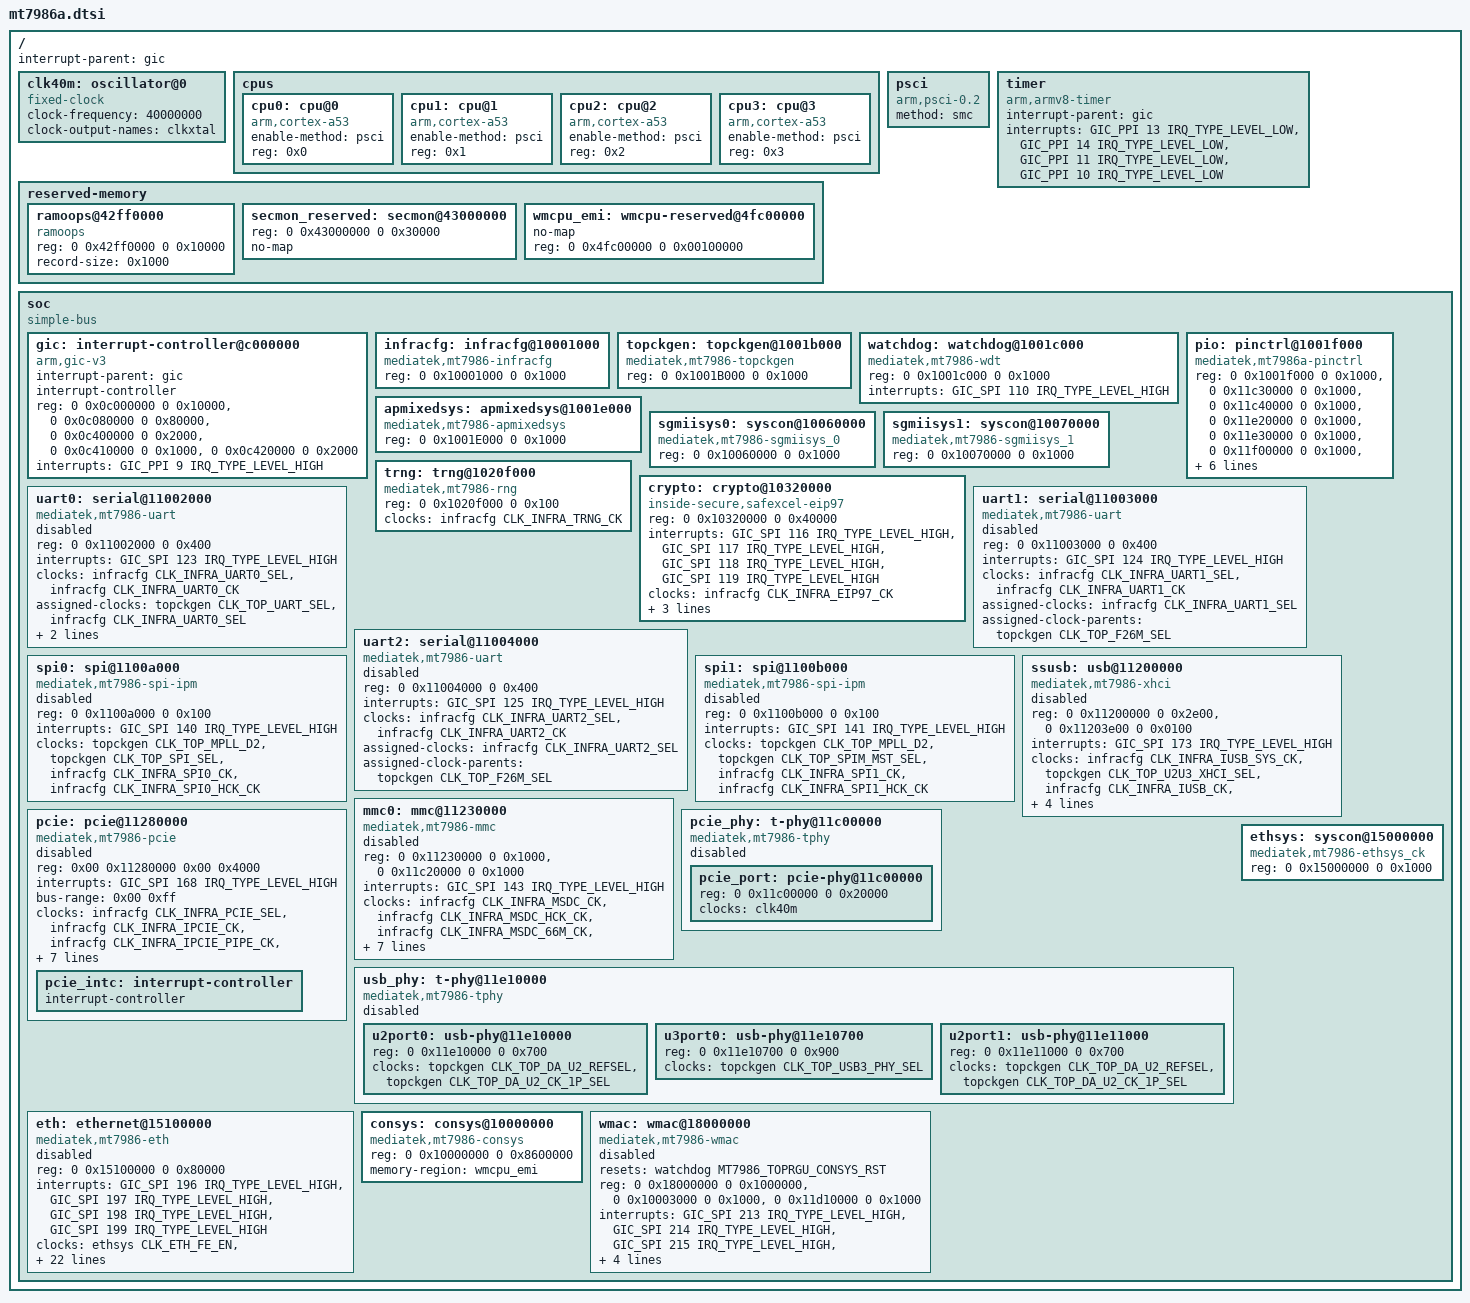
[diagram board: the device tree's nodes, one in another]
// SPDX-License-Identifier: (GPL-2.0 OR MIT)
/*
 * Copyright (C) 2021 MediaTek Inc.
 * Author: Sam.Shih <sam.shih@mediatek.com>
 */

#include <dt-bindings/clock/mt7986-clk.h>
#include <dt-bindings/interrupt-controller/irq.h>
#include <dt-bindings/interrupt-controller/arm-gic.h>
#include <dt-bindings/phy/phy.h>
#include <dt-bindings/reset/mt7986-resets.h>

/ {
	interrupt-parent = <&gic>;
	#address-cells = <2>;
	#size-cells = <2>;

	clk40m: oscillator@0 {
		compatible = "fixed-clock";
		clock-frequency = <40000000>;
		#clock-cells = <0>;
		clock-output-names = "clkxtal";
	};

	cpus {
		#address-cells = <1>;
		#size-cells = <0>;
		cpu0: cpu@0 {
			device_type = "cpu";
			compatible = "arm,cortex-a53";
			enable-method = "psci";
			reg = <0x0>;
			#cooling-cells = <2>;
		};

		cpu1: cpu@1 {
			device_type = "cpu";
			compatible = "arm,cortex-a53";
			enable-method = "psci";
			reg = <0x1>;
			#cooling-cells = <2>;
		};

		cpu2: cpu@2 {
			device_type = "cpu";
			compatible = "arm,cortex-a53";
			enable-method = "psci";
			reg = <0x2>;
			#cooling-cells = <2>;
		};

		cpu3: cpu@3 {
			device_type = "cpu";
			enable-method = "psci";
			compatible = "arm,cortex-a53";
			reg = <0x3>;
			#cooling-cells = <2>;
		};
	};

	psci {
		compatible  = "arm,psci-0.2";
		method      = "smc";
	};

	reserved-memory {
		#address-cells = <2>;
		#size-cells = <2>;
		ranges;

		/* 64 KiB reserved for ramoops/pstore */
		ramoops@42ff0000 {
			compatible = "ramoops";
			reg = <0 0x42ff0000 0 0x10000>;
			record-size = <0x1000>;
		};

		/* 192 KiB reserved for ARM Trusted Firmware (BL31) */
		secmon_reserved: secmon@43000000 {
			reg = <0 0x43000000 0 0x30000>;
			no-map;
		};

		wmcpu_emi: wmcpu-reserved@4fc00000 {
			no-map;
			reg = <0 0x4fc00000 0 0x00100000>;
		};
	};

	timer {
		compatible = "arm,armv8-timer";
		interrupt-parent = <&gic>;
		interrupts = <GIC_PPI 13 IRQ_TYPE_LEVEL_LOW>,
			     <GIC_PPI 14 IRQ_TYPE_LEVEL_LOW>,
			     <GIC_PPI 11 IRQ_TYPE_LEVEL_LOW>,
			     <GIC_PPI 10 IRQ_TYPE_LEVEL_LOW>;
	};

	soc {
		#address-cells = <2>;
		#size-cells = <2>;
		compatible = "simple-bus";
		ranges;

		gic: interrupt-controller@c000000 {
			compatible = "arm,gic-v3";
			#interrupt-cells = <3>;
			interrupt-parent = <&gic>;
			interrupt-controller;
			reg = <0 0x0c000000 0 0x10000>,  /* GICD */
			      <0 0x0c080000 0 0x80000>,  /* GICR */
			      <0 0x0c400000 0 0x2000>,   /* GICC */
			      <0 0x0c410000 0 0x1000>,   /* GICH */
			      <0 0x0c420000 0 0x2000>;   /* GICV */
			interrupts = <GIC_PPI 9 IRQ_TYPE_LEVEL_HIGH>;
		};

		infracfg: infracfg@10001000 {
			compatible = "mediatek,mt7986-infracfg", "syscon";
			reg = <0 0x10001000 0 0x1000>;
			#clock-cells = <1>;
		};

		topckgen: topckgen@1001b000 {
			compatible = "mediatek,mt7986-topckgen", "syscon";
			reg = <0 0x1001B000 0 0x1000>;
			#clock-cells = <1>;
		};

		watchdog: watchdog@1001c000 {
			compatible = "mediatek,mt7986-wdt",
				     "mediatek,mt6589-wdt";
			reg = <0 0x1001c000 0 0x1000>;
			interrupts = <GIC_SPI 110 IRQ_TYPE_LEVEL_HIGH>;
			#reset-cells = <1>;
		};

		pio: pinctrl@1001f000 {
			compatible = "mediatek,mt7986a-pinctrl";
			reg = <0 0x1001f000 0 0x1000>,
			      <0 0x11c30000 0 0x1000>,
			      <0 0x11c40000 0 0x1000>,
			      <0 0x11e20000 0 0x1000>,
			      <0 0x11e30000 0 0x1000>,
			      <0 0x11f00000 0 0x1000>,
			      <0 0x11f10000 0 0x1000>,
			      <0 0x1000b000 0 0x1000>;
			reg-names = "gpio", "iocfg_rt", "iocfg_rb", "iocfg_lt",
				    "iocfg_lb", "iocfg_tr", "iocfg_tl", "eint";
			gpio-controller;
			#gpio-cells = <2>;
			gpio-ranges = <&pio 0 0 100>;
			interrupt-controller;
			interrupts = <GIC_SPI 225 IRQ_TYPE_LEVEL_HIGH>;
			interrupt-parent = <&gic>;
			#interrupt-cells = <2>;
		};

		apmixedsys: apmixedsys@1001e000 {
			compatible = "mediatek,mt7986-apmixedsys";
			reg = <0 0x1001E000 0 0x1000>;
			#clock-cells = <1>;
		};

		sgmiisys0: syscon@10060000 {
			compatible = "mediatek,mt7986-sgmiisys_0",
				     "syscon";
			reg = <0 0x10060000 0 0x1000>;
			#clock-cells = <1>;
		};

		sgmiisys1: syscon@10070000 {
			compatible = "mediatek,mt7986-sgmiisys_1",
				     "syscon";
			reg = <0 0x10070000 0 0x1000>;
			#clock-cells = <1>;
		};

		trng: trng@1020f000 {
			compatible = "mediatek,mt7986-rng";
			reg = <0 0x1020f000 0 0x100>;
			clocks = <&infracfg CLK_INFRA_TRNG_CK>;
			clock-names = "rng";
			status = "okay";
		};

		crypto: crypto@10320000 {
			compatible = "inside-secure,safexcel-eip97";
			reg = <0 0x10320000 0 0x40000>;
			interrupts = <GIC_SPI 116 IRQ_TYPE_LEVEL_HIGH>,
				     <GIC_SPI 117 IRQ_TYPE_LEVEL_HIGH>,
				     <GIC_SPI 118 IRQ_TYPE_LEVEL_HIGH>,
				     <GIC_SPI 119 IRQ_TYPE_LEVEL_HIGH>;
			interrupt-names = "ring0", "ring1", "ring2", "ring3";
			clocks = <&infracfg CLK_INFRA_EIP97_CK>;
			clock-names = "infra_eip97_ck";
			assigned-clocks = <&topckgen CLK_TOP_EIP_B_SEL>;
			assigned-clock-parents = <&apmixedsys CLK_APMIXED_NET2PLL>;
			status = "okay";
		};

		uart0: serial@11002000 {
			compatible = "mediatek,mt7986-uart",
				     "mediatek,mt6577-uart";
			reg = <0 0x11002000 0 0x400>;
			interrupts = <GIC_SPI 123 IRQ_TYPE_LEVEL_HIGH>;
			clocks = <&infracfg CLK_INFRA_UART0_SEL>,
				 <&infracfg CLK_INFRA_UART0_CK>;
			clock-names = "baud", "bus";
			assigned-clocks = <&topckgen CLK_TOP_UART_SEL>,
					  <&infracfg CLK_INFRA_UART0_SEL>;
			assigned-clock-parents = <&topckgen CLK_TOP_XTAL>,
						 <&topckgen CLK_TOP_UART_SEL>;
			status = "disabled";
		};

		uart1: serial@11003000 {
			compatible = "mediatek,mt7986-uart",
				     "mediatek,mt6577-uart";
			reg = <0 0x11003000 0 0x400>;
			interrupts = <GIC_SPI 124 IRQ_TYPE_LEVEL_HIGH>;
			clocks = <&infracfg CLK_INFRA_UART1_SEL>,
				 <&infracfg CLK_INFRA_UART1_CK>;
			clock-names = "baud", "bus";
			assigned-clocks = <&infracfg CLK_INFRA_UART1_SEL>;
			assigned-clock-parents = <&topckgen CLK_TOP_F26M_SEL>;
			status = "disabled";
		};

		uart2: serial@11004000 {
			compatible = "mediatek,mt7986-uart",
				     "mediatek,mt6577-uart";
			reg = <0 0x11004000 0 0x400>;
			interrupts = <GIC_SPI 125 IRQ_TYPE_LEVEL_HIGH>;
			clocks = <&infracfg CLK_INFRA_UART2_SEL>,
				 <&infracfg CLK_INFRA_UART2_CK>;
			clock-names = "baud", "bus";
			assigned-clocks = <&infracfg CLK_INFRA_UART2_SEL>;
			assigned-clock-parents = <&topckgen CLK_TOP_F26M_SEL>;
			status = "disabled";
		};

		spi0: spi@1100a000 {
			compatible = "mediatek,mt7986-spi-ipm", "mediatek,spi-ipm";
			reg = <0 0x1100a000 0 0x100>;
			interrupts = <GIC_SPI 140 IRQ_TYPE_LEVEL_HIGH>;
			clocks = <&topckgen CLK_TOP_MPLL_D2>,
				 <&topckgen CLK_TOP_SPI_SEL>,
				 <&infracfg CLK_INFRA_SPI0_CK>,
				 <&infracfg CLK_INFRA_SPI0_HCK_CK>;
			clock-names = "parent-clk", "sel-clk", "spi-clk", "hclk";
			status = "disabled";
		};

		spi1: spi@1100b000 {
			compatible = "mediatek,mt7986-spi-ipm", "mediatek,spi-ipm";
			reg = <0 0x1100b000 0 0x100>;
			interrupts = <GIC_SPI 141 IRQ_TYPE_LEVEL_HIGH>;
			clocks = <&topckgen CLK_TOP_MPLL_D2>,
				 <&topckgen CLK_TOP_SPIM_MST_SEL>,
				 <&infracfg CLK_INFRA_SPI1_CK>,
				 <&infracfg CLK_INFRA_SPI1_HCK_CK>;
			clock-names = "parent-clk", "sel-clk", "spi-clk", "hclk";
			status = "disabled";
		};

		ssusb: usb@11200000 {
			compatible = "mediatek,mt7986-xhci",
				     "mediatek,mtk-xhci";
			reg = <0 0x11200000 0 0x2e00>,
			      <0 0x11203e00 0 0x0100>;
			reg-names = "mac", "ippc";
			interrupts = <GIC_SPI 173 IRQ_TYPE_LEVEL_HIGH>;
			clocks = <&infracfg CLK_INFRA_IUSB_SYS_CK>,
				 <&topckgen CLK_TOP_U2U3_XHCI_SEL>,
				 <&infracfg CLK_INFRA_IUSB_CK>,
				 <&infracfg CLK_INFRA_IUSB_133_CK>,
				 <&infracfg CLK_INFRA_IUSB_66M_CK>;
			clock-names = "sys_ck",
				      "xhci_ck",
				      "ref_ck",
				      "mcu_ck",
				      "dma_ck";
			phys = <&u2port0 PHY_TYPE_USB2>,
			       <&u3port0 PHY_TYPE_USB3>,
			       <&u2port1 PHY_TYPE_USB2>;
			status = "disabled";
		};

		mmc0: mmc@11230000 {
			compatible = "mediatek,mt7986-mmc";
			reg = <0 0x11230000 0 0x1000>,
			      <0 0x11c20000 0 0x1000>;
			interrupts = <GIC_SPI 143 IRQ_TYPE_LEVEL_HIGH>;
			clocks = <&infracfg CLK_INFRA_MSDC_CK>,
				 <&infracfg CLK_INFRA_MSDC_HCK_CK>,
				 <&infracfg CLK_INFRA_MSDC_66M_CK>,
				 <&infracfg CLK_INFRA_MSDC_133M_CK>;
			clock-names = "source", "hclk", "axi_cg", "ahb_cg";
			assigned-clocks = <&topckgen CLK_TOP_EMMC_416M_SEL>,
					  <&topckgen CLK_TOP_EMMC_250M_SEL>;
			assigned-clock-parents = <&apmixedsys CLK_APMIXED_MPLL>,
						 <&topckgen CLK_TOP_NET1PLL_D5_D2>;
			status = "disabled";
		};

		pcie: pcie@11280000 {
			compatible = "mediatek,mt7986-pcie",
				     "mediatek,mt8192-pcie";
			device_type = "pci";
			#address-cells = <3>;
			#size-cells = <2>;
			reg = <0x00 0x11280000 0x00 0x4000>;
			reg-names = "pcie-mac";
			interrupts = <GIC_SPI 168 IRQ_TYPE_LEVEL_HIGH>;
			bus-range = <0x00 0xff>;
			ranges = <0x82000000 0x00 0x20000000 0x00
				  0x20000000 0x00 0x10000000>;
			clocks = <&infracfg CLK_INFRA_PCIE_SEL>,
				 <&infracfg CLK_INFRA_IPCIE_CK>,
				 <&infracfg CLK_INFRA_IPCIE_PIPE_CK>,
				 <&infracfg CLK_INFRA_IPCIER_CK>,
				 <&infracfg CLK_INFRA_IPCIEB_CK>;
			status = "disabled";

			phys = <&pcie_port PHY_TYPE_PCIE>;
			phy-names = "pcie-phy";

			#interrupt-cells = <1>;
			interrupt-map-mask = <0 0 0 0x7>;
			interrupt-map = <0 0 0 1 &pcie_intc 0>,
					<0 0 0 2 &pcie_intc 1>,
					<0 0 0 3 &pcie_intc 2>,
					<0 0 0 4 &pcie_intc 3>;
			pcie_intc: interrupt-controller {
				#address-cells = <0>;
				#interrupt-cells = <1>;
				interrupt-controller;
			};
		};

		pcie_phy: t-phy@11c00000 {
			compatible = "mediatek,mt7986-tphy",
				     "mediatek,generic-tphy-v2";
			#address-cells = <2>;
			#size-cells = <2>;
			ranges;
			status = "disabled";

			pcie_port: pcie-phy@11c00000 {
				reg = <0 0x11c00000 0 0x20000>;
				clocks = <&clk40m>;
				clock-names = "ref";
				#phy-cells = <1>;
			};
		};

		usb_phy: t-phy@11e10000 {
			compatible = "mediatek,mt7986-tphy",
				     "mediatek,generic-tphy-v2";
			#address-cells = <2>;
			#size-cells = <2>;
			ranges;
			status = "disabled";

			u2port0: usb-phy@11e10000 {
				reg = <0 0x11e10000 0 0x700>;
				clocks = <&topckgen CLK_TOP_DA_U2_REFSEL>,
					 <&topckgen CLK_TOP_DA_U2_CK_1P_SEL>;
				clock-names = "ref", "da_ref";
				#phy-cells = <1>;
			};

			u3port0: usb-phy@11e10700 {
				reg = <0 0x11e10700 0 0x900>;
				clocks = <&topckgen CLK_TOP_USB3_PHY_SEL>;
				clock-names = "ref";
				#phy-cells = <1>;
			};

			u2port1: usb-phy@11e11000 {
				reg = <0 0x11e11000 0 0x700>;
				clocks = <&topckgen CLK_TOP_DA_U2_REFSEL>,
					 <&topckgen CLK_TOP_DA_U2_CK_1P_SEL>;
				clock-names = "ref", "da_ref";
				#phy-cells = <1>;
			};
		};

		ethsys: syscon@15000000 {
			 #address-cells = <1>;
			 #size-cells = <1>;
			 compatible = "mediatek,mt7986-ethsys_ck",
				      "syscon";
			 reg = <0 0x15000000 0 0x1000>;
			 #clock-cells = <1>;
			 #reset-cells = <1>;
		};

		eth: ethernet@15100000 {
			compatible = "mediatek,mt7986-eth";
			reg = <0 0x15100000 0 0x80000>;
			interrupts = <GIC_SPI 196 IRQ_TYPE_LEVEL_HIGH>,
				     <GIC_SPI 197 IRQ_TYPE_LEVEL_HIGH>,
				     <GIC_SPI 198 IRQ_TYPE_LEVEL_HIGH>,
				     <GIC_SPI 199 IRQ_TYPE_LEVEL_HIGH>;
			clocks = <&ethsys CLK_ETH_FE_EN>,
				 <&ethsys CLK_ETH_GP2_EN>,
				 <&ethsys CLK_ETH_GP1_EN>,
				 <&ethsys CLK_ETH_WOCPU1_EN>,
				 <&ethsys CLK_ETH_WOCPU0_EN>,
				 <&sgmiisys0 CLK_SGMII0_TX250M_EN>,
				 <&sgmiisys0 CLK_SGMII0_RX250M_EN>,
				 <&sgmiisys0 CLK_SGMII0_CDR_REF>,
				 <&sgmiisys0 CLK_SGMII0_CDR_FB>,
				 <&sgmiisys1 CLK_SGMII1_TX250M_EN>,
				 <&sgmiisys1 CLK_SGMII1_RX250M_EN>,
				 <&sgmiisys1 CLK_SGMII1_CDR_REF>,
				 <&sgmiisys1 CLK_SGMII1_CDR_FB>,
				 <&topckgen CLK_TOP_NETSYS_SEL>,
				 <&topckgen CLK_TOP_NETSYS_500M_SEL>;
			clock-names = "fe", "gp2", "gp1", "wocpu1", "wocpu0",
				      "sgmii_tx250m", "sgmii_rx250m",
				      "sgmii_cdr_ref", "sgmii_cdr_fb",
				      "sgmii2_tx250m", "sgmii2_rx250m",
				      "sgmii2_cdr_ref", "sgmii2_cdr_fb",
				      "netsys0", "netsys1";
			assigned-clocks = <&topckgen CLK_TOP_NETSYS_2X_SEL>,
					  <&topckgen CLK_TOP_SGM_325M_SEL>;
			assigned-clock-parents = <&apmixedsys CLK_APMIXED_NET2PLL>,
						 <&apmixedsys CLK_APMIXED_SGMPLL>;
			mediatek,ethsys = <&ethsys>;
			mediatek,sgmiisys = <&sgmiisys0>, <&sgmiisys1>;
			#reset-cells = <1>;
			#address-cells = <1>;
			#size-cells = <0>;
			status = "disabled";
		};

		consys: consys@10000000 {
			compatible = "mediatek,mt7986-consys";
			reg = <0 0x10000000 0 0x8600000>;
			memory-region = <&wmcpu_emi>;
		};

		wmac: wmac@18000000 {
			compatible = "mediatek,mt7986-wmac", "mediatek,wbsys";
			resets = <&watchdog MT7986_TOPRGU_CONSYS_RST>;
			reset-names = "consys";
			reg = <0 0x18000000 0 0x1000000>,
			      <0 0x10003000 0 0x1000>,
			      <0 0x11d10000 0 0x1000>;
			interrupts = <GIC_SPI 213 IRQ_TYPE_LEVEL_HIGH>,
				     <GIC_SPI 214 IRQ_TYPE_LEVEL_HIGH>,
				     <GIC_SPI 215 IRQ_TYPE_LEVEL_HIGH>,
				     <GIC_SPI 217 IRQ_TYPE_LEVEL_HIGH>;
			clocks = <&topckgen CLK_TOP_CONN_MCUSYS_SEL>,
				 <&topckgen CLK_TOP_AP2CNN_HOST_SEL>;
			clock-names = "mcu", "ap2conn";
			memory-region = <&wmcpu_emi>;
			status = "disabled";
		};
	};

};
